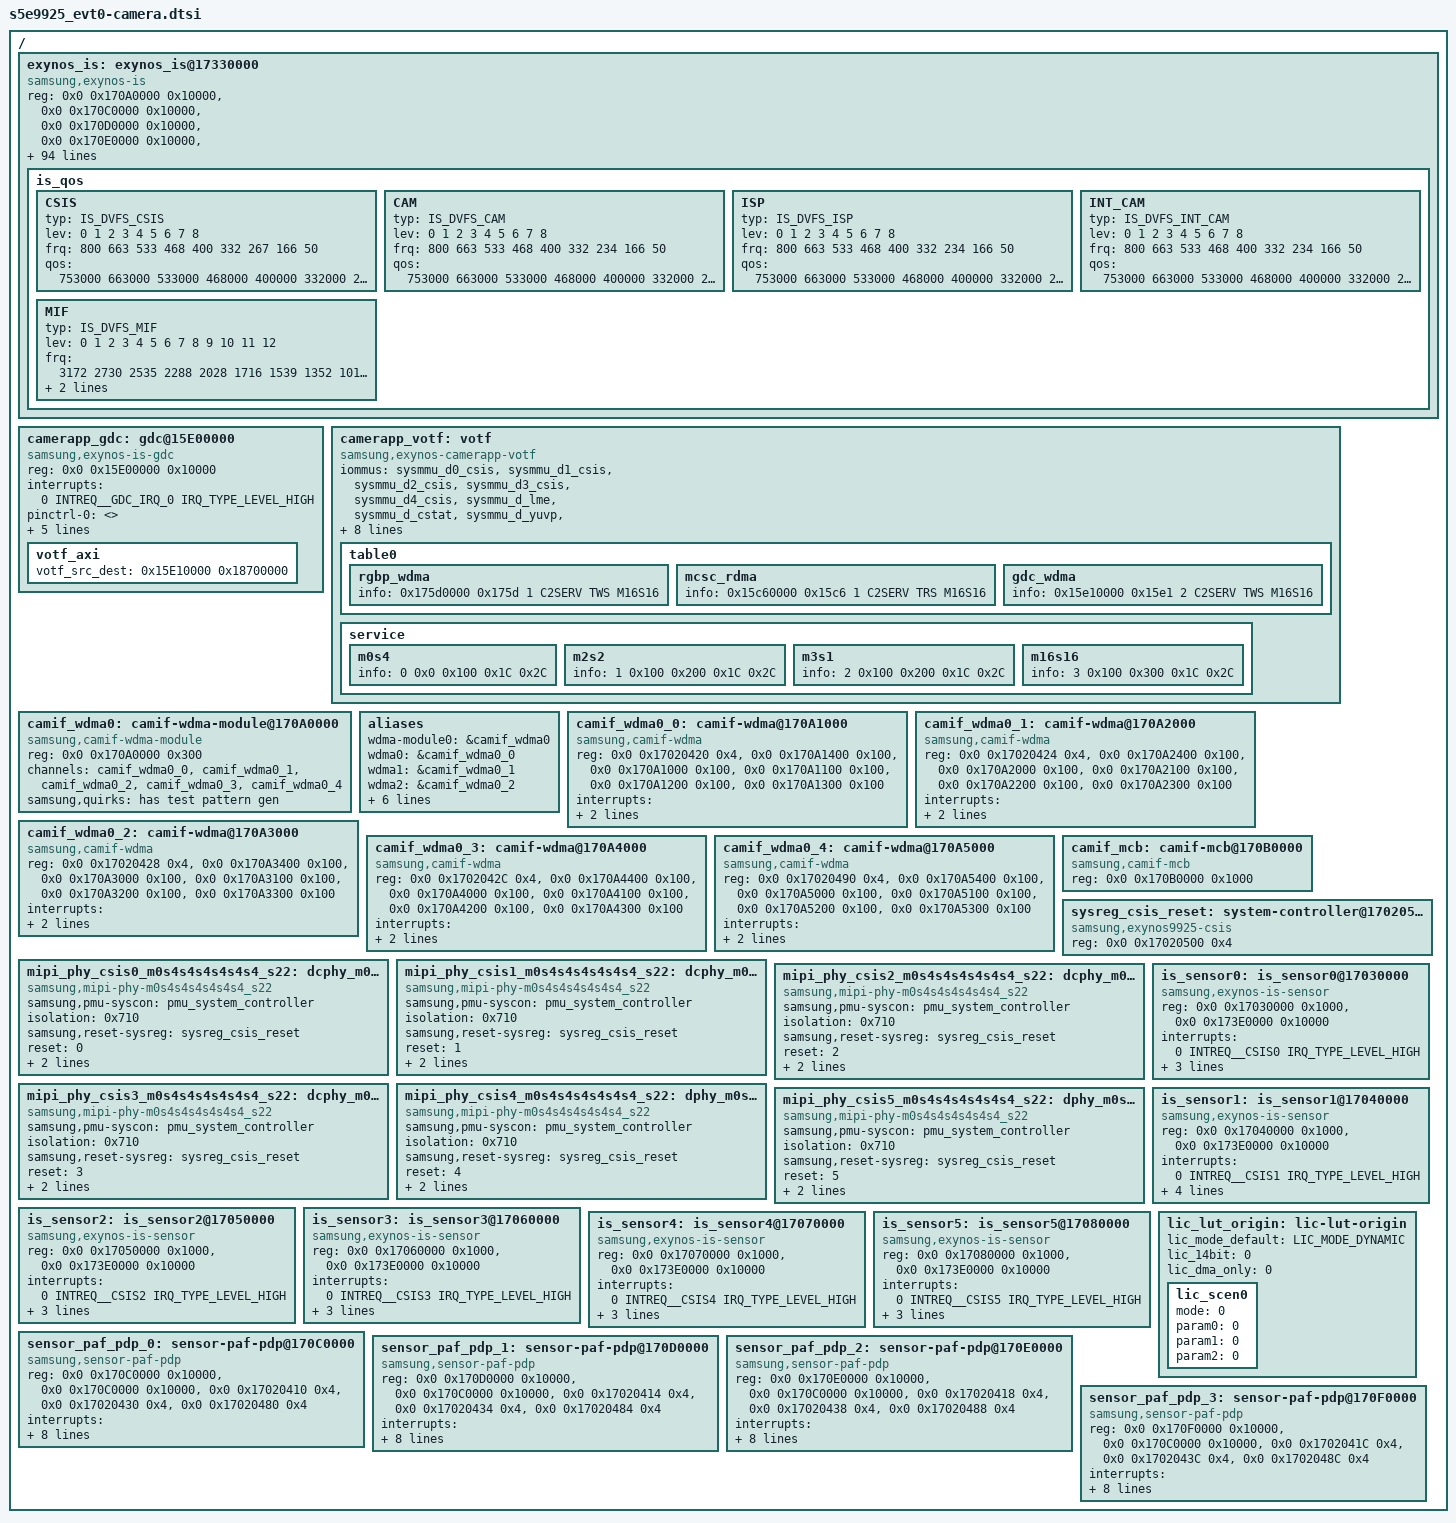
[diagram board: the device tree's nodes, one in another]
/*
 * SAMSUNG EXYNOS9925 SoC camera device tree source
 *
 * Copyright (c) 2020 Samsung Electronics Co., Ltd.
 *		http://www.samsung.com
 *
 * SAMSUNG EXYNOS9925 SoC camera device nodes are listed in this file.
 * EXYNOS9925 based board files can include this file and provide
 * values for board specfic bindings.
 *
 * This program is free software; you can redistribute it and/or modify
 * it under the terms of the GNU General Public License version 2 as
 * published by the Free Software Foundation.
 */

#include <dt-bindings/clock/s5e9925_evt0.h>
#include <dt-bindings/interrupt-controller/arm-gic.h>
#include <dt-bindings/interrupt-controller/s5e9925_evt0.h>
#include <dt-bindings/camera/exynos_is_dt.h>
#include <dt-bindings/camera/votf.h>
#include "s5e9925_evt0-pinctrl.dtsi"

/ {
	exynos_is: exynos_is@17330000 {
		compatible = "samsung,exynos-is";
		reg = <0x0 0x170A0000 0x10000>, /* CSIS_WDMA */
			<0x0 0x170C0000 0x10000>, /* PDP_CORE0 */
			<0x0 0x170D0000 0x10000>, /* PDP_CORE1 */
			<0x0 0x170E0000 0x10000>, /* PDP_CORE2 */
			<0x0 0x170F0000 0x10000>, /* PDP_CORE3 */
			<0x0 0x18440000 0x10000>, /* CSTAT0 */
			<0x0 0x18450000 0x10000>, /* CSTAT1 */
			<0x0 0x18460000 0x10000>, /* CSTAT2 */
			<0x0 0x18470000 0x10000>, /* CSTAT3 */
			<0x0 0x170A0000 0x10000>, /* ZSL/STRIP DMA  */
			<0x0 0x17730000 0x10000>, /* LME */
			<0x0 0x15F80000 0x10000>, /* BYRP */
			<0x0 0x175B0000 0x10000>, /* RGBP */
			<0x0 0x17430000 0x10000>, /* DRCP */
			<0x0 0x17B00000 0x10000>, /* MCFP */
			<0x0 0x18080000 0x10000>, /* YUVP */
			<0x0 0x15C40000 0x10000>; /* MCSC */
		interrupts = <0 INTREQ__CSTAT_CH0_0 IRQ_TYPE_LEVEL_HIGH>, /*CSTAT0_0 */
			<0 INTREQ__CSTAT_CH0_1 IRQ_TYPE_LEVEL_HIGH>,      /* CSTAT0_1 */
			<0 INTREQ__CSTAT_CH1_0 IRQ_TYPE_LEVEL_HIGH>,      /* CSTAT1_0 */
			<0 INTREQ__CSTAT_CH1_1 IRQ_TYPE_LEVEL_HIGH>,      /* CSTAT1_1 */
			<0 INTREQ__CSTAT_CH2_0 IRQ_TYPE_LEVEL_HIGH>,      /* CSTAT2_0 */
			<0 INTREQ__CSTAT_CH2_1 IRQ_TYPE_LEVEL_HIGH>,      /* CSTAT2_1 */
			<0 INTREQ__CSTAT_CH3_0 IRQ_TYPE_LEVEL_HIGH>,      /* CSTAT3_0 */
			<0 INTREQ__CSTAT_CH3_1 IRQ_TYPE_LEVEL_HIGH>,      /* CSTAT3_1 */
			<0 INTREQ__LME_O_INT0 IRQ_TYPE_LEVEL_HIGH>,       /* LME_0 */
			<0 INTREQ__BYRP_0 IRQ_TYPE_LEVEL_HIGH>,           /* BYRP_0 */
			<0 INTREQ__BYRP_1 IRQ_TYPE_LEVEL_HIGH>,           /* BYRP_1 */
			<0 INTREQ__RGBP_0 IRQ_TYPE_LEVEL_HIGH>,           /* RGBP_0 */
			<0 INTREQ__RGBP_1 IRQ_TYPE_LEVEL_HIGH>,           /* RGBP_1 */
			<0 INTREQ__MCFP_0 IRQ_TYPE_LEVEL_HIGH>,           /* MCFP_0 */
			<0 INTREQ__MCFP_1 IRQ_TYPE_LEVEL_HIGH>,           /* MCFP_1 */
			<0 INTREQ__YUVP_0 IRQ_TYPE_LEVEL_HIGH>,           /* YUVP_0 */
			<0 INTREQ__YUVP_1 IRQ_TYPE_LEVEL_HIGH>,           /* YUVP_1 */
			<0 INTREQ__DRCP_0 IRQ_TYPE_LEVEL_HIGH>,           /* DRCP_0 */
			<0 INTREQ__DRCP_1 IRQ_TYPE_LEVEL_HIGH>,           /* DRCP_1 */
			<0 INTREQ__MCSC_INTREQ_0 IRQ_TYPE_LEVEL_HIGH>,    /* MCSC_0 */
			<0 INTREQ__MCSC_INTREQ_1 IRQ_TYPE_LEVEL_HIGH>;    /* MCSC_1 */
		pinctrl-names = "default","release";
		pinctrl-0 = <>;
		pinctrl-1 = <>;
		clocks = <&clock GATE_DFTMUX_CMU_QCH_CIS_CLK0>,
		      <&clock GATE_DFTMUX_CMU_QCH_CIS_CLK1>,
		      <&clock GATE_DFTMUX_CMU_QCH_CIS_CLK2>,
		      <&clock GATE_DFTMUX_CMU_QCH_CIS_CLK3>,
		      <&clock GATE_DFTMUX_CMU_QCH_CIS_CLK4>,
		      <&clock GATE_DFTMUX_CMU_QCH_CIS_CLK5>,
		      <&clock GATE_DFTMUX_CMU_QCH_CIS_CLK6>,
		      <&clock GATE_DFTMUX_CMU_QCH_CIS_CLK7>,

		      <&clock DOUT_DIV_CLKCMU_CIS_CLK0>,
		      <&clock DOUT_DIV_CLKCMU_CIS_CLK1>,
		      <&clock DOUT_DIV_CLKCMU_CIS_CLK2>,
		      <&clock DOUT_DIV_CLKCMU_CIS_CLK3>,
		      <&clock DOUT_DIV_CLKCMU_CIS_CLK4>,
		      <&clock DOUT_DIV_CLKCMU_CIS_CLK5>,
		      <&clock DOUT_DIV_CLKCMU_CIS_CLK6>,
		      <&clock DOUT_DIV_CLKCMU_CIS_CLK7>,

		      <&clock GATE_CSIS_PDP_QCH_DMA>,

		      <&clock GATE_MIPI_PHY_LINK_WRAP_QCH_CSIS0>,
		      <&clock GATE_MIPI_PHY_LINK_WRAP_QCH_CSIS1>,
		      <&clock GATE_MIPI_PHY_LINK_WRAP_QCH_CSIS2>,
		      <&clock GATE_MIPI_PHY_LINK_WRAP_QCH_CSIS3>,
		      <&clock GATE_MIPI_PHY_LINK_WRAP_QCH_CSIS4>,
		      <&clock GATE_MIPI_PHY_LINK_WRAP_QCH_CSIS5>,
		      <&clock GATE_MIPI_PHY_LINK_WRAP_QCH_CSIS6>,

		      <&clock GATE_CSIS_PDP_QCH_PDP>,
		      <&clock GATE_LH_AST_SI_OTF0_CSISCSTAT_QCH>,
		      <&clock GATE_LH_AST_SI_OTF1_CSISCSTAT_QCH>,
		      <&clock GATE_LH_AST_SI_OTF2_CSISCSTAT_QCH>,
		      <&clock GATE_LH_AST_SI_OTF3_CSISCSTAT_QCH>,
		      <&clock GATE_LME_QCH_0>,
		      <&clock GATE_LME_QCH_1>,
		      <&clock GATE_MCFP_QCH>,
		      <&clock GATE_YUVP_QCH>,
		      <&clock GATE_MCSC_QCH>;
		      /* <&clock GATE_GDC_QCH>; */
		clock-names = "GATE_DFTMUX_CMU_QCH_CIS_CLK0",
			"GATE_DFTMUX_CMU_QCH_CIS_CLK1",
			"GATE_DFTMUX_CMU_QCH_CIS_CLK2",
			"GATE_DFTMUX_CMU_QCH_CIS_CLK3",
			"GATE_DFTMUX_CMU_QCH_CIS_CLK4",
			"GATE_DFTMUX_CMU_QCH_CIS_CLK5",
			"GATE_DFTMUX_CMU_QCH_CIS_CLK6",
			"GATE_DFTMUX_CMU_QCH_CIS_CLK7",

			"DOUT_DIV_CLKCMU_CIS_CLK0",
			"DOUT_DIV_CLKCMU_CIS_CLK1",
			"DOUT_DIV_CLKCMU_CIS_CLK2",
			"DOUT_DIV_CLKCMU_CIS_CLK3",
			"DOUT_DIV_CLKCMU_CIS_CLK4",
			"DOUT_DIV_CLKCMU_CIS_CLK5",
			"DOUT_DIV_CLKCMU_CIS_CLK6",
			"DOUT_DIV_CLKCMU_CIS_CLK7",

			"GATE_CSIS_PDP_QCH_DMA",

			"GATE_MIPI_PHY_LINK_WRAP_QCH_CSIS0",
			"GATE_MIPI_PHY_LINK_WRAP_QCH_CSIS1",
			"GATE_MIPI_PHY_LINK_WRAP_QCH_CSIS2",
			"GATE_MIPI_PHY_LINK_WRAP_QCH_CSIS3",
			"GATE_MIPI_PHY_LINK_WRAP_QCH_CSIS4",
			"GATE_MIPI_PHY_LINK_WRAP_QCH_CSIS5",
			"GATE_MIPI_PHY_LINK_WRAP_QCH_CSIS6",

			"GATE_CSIS_PDP_QCH_PDP",
			"GATE_LH_AST_SI_OTF0_CSISCSTAT_QCH",
			"GATE_LH_AST_SI_OTF1_CSISCSTAT_QCH",
			"GATE_LH_AST_SI_OTF2_CSISCSTAT_QCH",
			"GATE_LH_AST_SI_OTF3_CSISCSTAT_QCH",
			"GATE_LME_QCH_0",
			"GATE_LME_QCH_1",
			"GATE_MCFP_QCH",
			"GATE_YUVP_QCH",
			"GATE_MCSC_QCH";
			/* "GATE_GDC_QCH"; */
		status = "ok";
		iommus = <&sysmmu_d0_csis>,
			<&sysmmu_d1_csis>,
			<&sysmmu_d2_csis>,
			<&sysmmu_d3_csis>,
			<&sysmmu_d4_csis>,
			<&sysmmu_d_lme>,
			<&sysmmu_d_cstat>,
			<&sysmmu_d_yuvp>,
			<&sysmmu_d1_mcsc>,
			<&sysmmu_d2_mcsc>,
			<&sysmmu_d0_mcfp>,
			<&sysmmu_d1_mcfp>,
			<&sysmmu_d2_mcfp>,
			<&sysmmu_d3_mcfp>,
			<&sysmmu_d4_mcfp>,
			<&sysmmu_d5_mcfp>,
			<&sysmmu_d0_rgbp>,
			<&sysmmu_d1_rgbp>,
			<&sysmmu_d_drcp>,
			<&sysmmu_d_byrp>;
		samsung,iommu-group = <&iommu_group_is>;
		#cooling-cells = <2>; /* min followed by max */
		ewf-index = <EWF_GRP_CAM>;
		list-scen-bts = "camera_default", "camera_heavy";
		num_of_3aa = <4>;
		num_of_lme = <1>;
		num_of_isp = <0>;
		num_of_byrp = <1>;
		num_of_rgbp = <1>;
		num_of_mcsc = <1>;
		num_of_vra = <0>;
		num_of_clh = <0>;
		num_of_ypp = <1>;
		num_of_mcfp = <1>;

		memory-region = <&camera_bin>;
		samsung,tzmp;

		is_qos {
			CSIS { /* CSIS, CSTAT */
				typ = <IS_DVFS_CSIS>;
				lev = <0      1      2      3      4      5      6      7      8>;
				frq = <800    663    533    468    400    332    267    166    50>;
				qos = <753000 663000 533000 468000 400000 332000 267000 166000 50000>;
			};

			CAM { /* BYRP, RGBP, MCSC, GDC */
				typ = <IS_DVFS_CAM>;
				lev = <0      1      2      3      4      5      6      7      8>;
				frq = <800    663    533    468    400    332    234    166    50>;
				qos = <753000 663000 533000 468000 400000 332000 234000 166000 50000>;
			};

			ISP { /* MCFP, YUVP */
				typ = <IS_DVFS_ISP>;
				lev = <0      1      2      3      4      5      6      7      8>;
				frq = <800    663    533    468    400    332    234    166    50>;
				qos = <753000 663000 533000 468000 400000 332000 234000 166000 50000>;
			};

			INT_CAM { /* LME */
				typ = <IS_DVFS_INT_CAM>;
				lev = <0      1      2      3      4      5      6      7      8>;
				frq = <800    663    533    468    400    332    234    166    50>;
				qos = <753000 663000 533000 468000 400000 332000 234000 166000 50000>;
			};

			MIF {
				typ = <IS_DVFS_MIF>;
				lev = <0       1       2       3       4       5       6       7       8       9      10     11     12>;
				frq = <3172    2730    2535    2288    2028    1716    1539    1352    1014    845    676    546    421>;
				qos = <3172000 2730000 2535000 2288000 2028000 1716000 1539000 1352000 1014000 845000 676000 546000 421000>;
			};
		};
	};

	camerapp_gdc: gdc@15E00000 {
		compatible = "samsung,exynos-is-gdc";
		reg = <0x0 0x15E00000 0x10000>; /* GDC */
		interrupts = <0 INTREQ__GDC_IRQ_0 IRQ_TYPE_LEVEL_HIGH>; /* GDC */
		pinctrl-names = "default","release";
		pinctrl-0 = <>;
		pinctrl-1 = <>;
		clocks = <&clock GATE_MCSC_QCH>;
		clock-names = "gate";
		status = "okay";
		iommus = <&sysmmu_d0_mcsc>;
		samsung,iommu-group = <&iommu_group_camerapp_gdc>;
		#cooling-cells = <2>; /* min followed by max */
		dma-coherent;

		votf_axi {
			votf_src_dest = <0x15E10000 0x18700000>;
		};
	};

	camerapp_votf: votf {
		compatible = "samsung,exynos-camerapp-votf";
		iommus = <&sysmmu_d0_csis>,
			<&sysmmu_d1_csis>,
			<&sysmmu_d2_csis>,
			<&sysmmu_d3_csis>,
			<&sysmmu_d4_csis>,
			<&sysmmu_d_lme>,
			<&sysmmu_d_cstat>,
			<&sysmmu_d_yuvp>,
			<&sysmmu_d1_mcsc>,
			<&sysmmu_d2_mcsc>,
			<&sysmmu_d0_mcfp>,
			<&sysmmu_d1_mcfp>,
			<&sysmmu_d2_mcfp>,
			<&sysmmu_d3_mcfp>,
			<&sysmmu_d4_mcfp>,
			<&sysmmu_d5_mcfp>,
			<&sysmmu_d0_rgbp>,
			<&sysmmu_d1_rgbp>,
			<&sysmmu_d_drcp>,
			<&sysmmu_d_byrp>;
		samsung,iommu-group = <&iommu_group_is>;
		status = "okay";
		use_axi;

		table0{
			/* base address, ip num, id cnt, C2SERV/C2AGENT, TWS/TRS, module type */
			/*
			csis_wdma0 { info = <0x17380000 0x1738 16 C2SERV TWS M16S16>; };
			csis_wdma1 { info = <0x17390000 0x1739 4 C2SERV TWS M16S16>; };
			pdp_rdma   { info = <0x173a0000 0x173a 4 C2SERV TRS M16S16>; };
			byrp_wdma  { info = <0x15fa0000 0x15fa 2 C2SERV TWS M16S16>; };
			byrp_rdma  { info = <0x15fc0000 0x15fc 1 C2SERV TRS M16S16>; };
			cstat_wdma0 { info = <0x18510000 0x1851 16 C2SERV TWS M16S16>; };
			cstat_wdma1 { info = <0x18520000 0x1852 16 C2SERV TWS M16S16>; };
			cstat_wdma2 { info = <0x18530000 0x1853 4 C2SERV TWS M16S16>; };
			cstat_rdma { info = <0x18500000 0x1850 4 C2SERV TRS M16S16>; };
			rgbp_rdma { info = <0x175c0000 0x175c 4 C2SERV TWS M16S16>; };
			*/
			rgbp_wdma { info = <0x175d0000 0x175d 1 C2SERV TWS M16S16>; };
			mcsc_rdma  { info = <0x15c60000 0x15c6 1 C2SERV TRS M16S16>; };
			gdc_wdma   { info = <0x15e10000 0x15e1 2 C2SERV TWS M16S16>; };
			/*
			mcsc_wdma  { info = <0x16c50000 0x15c5 16 C2SERV TWS M16S16>; };
			gdc_rdma   { info = <0x15e20000 0x15e2 2 C2SERV TRS M16S16>; };
			lme_rdma   { info = <0x17740000 0x1774 16 C2SERV TRS M16S16>; };
			*/
		};

		service {
			/* num, tws addr, trs addr, tws gap, trs gap */
			m0s4 { info = <0 0x0 0x100 0x1C 0x2C>; };
			m2s2 { info = <1 0x100 0x200 0x1C 0x2C>; };
			m3s1 { info = <2 0x100 0x200 0x1C 0x2C>; };
			m16s16 { info = <3 0x100 0x300 0x1C 0x2C>; };
		};
	};

	camif_wdma0: camif-wdma-module@170A0000 {
		compatible = "samsung,camif-wdma-module";
		reg = <0x0 0x170A0000 0x300>;
		reg-names = "ctl";
		channels = <&camif_wdma0_0>,
			<&camif_wdma0_1>,
			<&camif_wdma0_2>,
			<&camif_wdma0_3>,
			<&camif_wdma0_4>;
		samsung,quirks = "has test pattern gen";
	};

	aliases {
		wdma-module0 = &camif_wdma0;
	};

	camif_wdma0_0: camif-wdma@170A1000 {
		compatible = "samsung,camif-wdma";
		reg = <0x0 0x17020420 0x4>,	/* input MUX */
			<0x0 0x170A1400 0x100>,	/* CTL */
			<0x0 0x170A1000 0x100>,	/* VC0 */
			<0x0 0x170A1100 0x100>,	/* VC1 */
			<0x0 0x170A1200 0x100>,	/* VC2 */
			<0x0 0x170A1300 0x100>;	/* VC3 */
		reg-names = "mux", "ctl", "vc0", "vc1", "vc2", "vc3";
		interrupts = <GIC_SPI INTREQ__CSIS_DMA0 IRQ_TYPE_LEVEL_HIGH>;
		interrupt-names = "dma";
		module = <&camif_wdma0>;
	};

	camif_wdma0_1: camif-wdma@170A2000 {
		compatible = "samsung,camif-wdma";
		reg = <0x0 0x17020424 0x4>,	/* input MUX */
			<0x0 0x170A2400 0x100>,	/* CTL */
			<0x0 0x170A2000 0x100>,	/* VC0 */
			<0x0 0x170A2100 0x100>,	/* VC1 */
			<0x0 0x170A2200 0x100>,	/* VC2 */
			<0x0 0x170A2300 0x100>;	/* VC3 */
		reg-names = "mux", "ctl", "vc0", "vc1", "vc2", "vc3";
		interrupts = <GIC_SPI INTREQ__CSIS_DMA1 IRQ_TYPE_LEVEL_HIGH>;
		interrupt-names = "dma";
		module = <&camif_wdma0>;
	};

	camif_wdma0_2: camif-wdma@170A3000 {
		compatible = "samsung,camif-wdma";
		reg = <0x0 0x17020428 0x4>,	/* input MUX */
			<0x0 0x170A3400 0x100>,	/* CTL */
			<0x0 0x170A3000 0x100>,	/* VC0 */
			<0x0 0x170A3100 0x100>,	/* VC1 */
			<0x0 0x170A3200 0x100>,	/* VC2 */
			<0x0 0x170A3300 0x100>;	/* VC3 */
		reg-names = "mux", "ctl", "vc0", "vc1", "vc2", "vc3";
		interrupts = <GIC_SPI INTREQ__CSIS_DMA2 IRQ_TYPE_LEVEL_HIGH>;
		interrupt-names = "dma";
		module = <&camif_wdma0>;
	};

	camif_wdma0_3: camif-wdma@170A4000 {
		compatible = "samsung,camif-wdma";
		reg = <0x0 0x1702042C 0x4>,	/* input MUX */
			<0x0 0x170A4400 0x100>,	/* CTL */
			<0x0 0x170A4000 0x100>,	/* VC0 */
			<0x0 0x170A4100 0x100>,	/* VC1 */
			<0x0 0x170A4200 0x100>,	/* VC2 */
			<0x0 0x170A4300 0x100>;	/* VC3 */
		reg-names = "mux", "ctl", "vc0", "vc1", "vc2", "vc3";
		interrupts = <GIC_SPI INTREQ__CSIS_DMA3 IRQ_TYPE_LEVEL_HIGH>;
		interrupt-names = "dma";
		module = <&camif_wdma0>;
	};

	camif_wdma0_4: camif-wdma@170A5000 {
		compatible = "samsung,camif-wdma";
		reg = <0x0 0x17020490 0x4>,	/* input MUX */
			<0x0 0x170A5400 0x100>,	/* CTL */
			<0x0 0x170A5000 0x100>,	/* VC0 */
			<0x0 0x170A5100 0x100>,	/* VC1 */
			<0x0 0x170A5200 0x100>,	/* VC2 */
			<0x0 0x170A5300 0x100>;	/* VC3 */
		reg-names = "mux", "ctl", "vc0", "vc1", "vc2", "vc3";
		interrupts = <GIC_SPI INTREQ__CSIS_DMA4 IRQ_TYPE_LEVEL_HIGH>;
		interrupt-names = "dma";
		module = <&camif_wdma0>;
	};

	aliases {
		wdma0 = &camif_wdma0_0;
		wdma1 = &camif_wdma0_1;
		wdma2 = &camif_wdma0_2;
		wdma3 = &camif_wdma0_3;
		wdma4 = &camif_wdma0_4;
	};

	camif_mcb: camif-mcb@170B0000 {
		compatible = "samsung,camif-mcb";
		reg = <0x0 0x170B0000 0x1000>;
	};

	sysreg_csis_reset: system-controller@17020500 {
		compatible = "samsung,exynos9925-csis", "syscon";
		reg = <0x0 0x17020500 0x4>;
	};

	mipi_phy_csis0_m0s4s4s4s4s4s4_s22: dcphy_m0s4s4s4s4s4s4_s22_csi0@17020500 {
		/* DPHY 6.5 Gbps 4lane */
		/* CPHY 6.5 Gbps 3lane */
		compatible = "samsung,mipi-phy-m0s4s4s4s4s4s4_s22";
		samsung,pmu-syscon = <&pmu_system_controller>;
		isolation = <0x710>; /* PMU address offset */
		samsung,reset-sysreg = <&sysreg_csis_reset>;
		reset = <0>; /* reset bit */
		reg = <0x0 0x173E1300 0x500>;
		owner = <1>; /* 0: DSI,  1: CSI */
		#phy-cells = <1>;
	};

	mipi_phy_csis1_m0s4s4s4s4s4s4_s22: dcphy_m0s4s4s4s4s4s4_s22_csi1@17020500 {
		/* DPHY 6.5 Gbps 4lane */
		/* CPHY 6.5 Gbps 3lane */
		compatible = "samsung,mipi-phy-m0s4s4s4s4s4s4_s22";
		samsung,pmu-syscon = <&pmu_system_controller>;
		isolation = <0x710>; /* PMU address offset */
		samsung,reset-sysreg = <&sysreg_csis_reset>;
		reset = <1>; /* reset bit */
		reg = <0x0 0x173E1B00 0x500>;
		owner = <1>; /* 0: DSI,  1: CSI */
		#phy-cells = <1>;
	};

	mipi_phy_csis2_m0s4s4s4s4s4s4_s22: dcphy_m0s4s4s4s4s4s4_s22_csi2@17020500 {
		/* DPHY 6.5 Gbps 4lane */
		/* CPHY 6.5 Gbps 3lane */
		compatible = "samsung,mipi-phy-m0s4s4s4s4s4s4_s22";
		samsung,pmu-syscon = <&pmu_system_controller>;
		isolation = <0x710>; /* PMU address offset */
		samsung,reset-sysreg = <&sysreg_csis_reset>;
		reset = <2>; /* reset bit */
		reg = <0x0 0x173E2300 0x500>;
		owner = <1>; /* 0: DSI,  1: CSI */
		#phy-cells = <1>;
	};

	mipi_phy_csis3_m0s4s4s4s4s4s4_s22: dcphy_m0s4s4s4s4s4s4_s22_csi3@17020500 {
		/* DPHY 6.5 Gbps 4lane */
		/* CPHY 6.5 Gbps 3lane */
		compatible = "samsung,mipi-phy-m0s4s4s4s4s4s4_s22";
		samsung,pmu-syscon = <&pmu_system_controller>;
		isolation = <0x710>; /* PMU address offset */
		samsung,reset-sysreg = <&sysreg_csis_reset>;
		reset = <3>; /* reset bit */
		reg = <0x0 0x173E2B00 0x500>;
		owner = <1>; /* 0: DSI,  1: CSI */
		#phy-cells = <1>;
	};

	mipi_phy_csis4_m0s4s4s4s4s4s4_s22: dphy_m0s4s4s4s4s4s4_s22_csi4@17020500 {
		/* DPHY 6.5 Gbps 4lane */
		/* CPHY 6.5 Gbps 3lane */
		compatible = "samsung,mipi-phy-m0s4s4s4s4s4s4_s22";
		samsung,pmu-syscon = <&pmu_system_controller>;
		isolation = <0x710>; /* PMU address offset */
		samsung,reset-sysreg = <&sysreg_csis_reset>;
		reset = <4>; /* reset bit */
		reg = <0x0 0x173E3300 0x500>;
		owner = <1>; /* 0: DSI,  1: CSI */
		#phy-cells = <1>;
	};

	mipi_phy_csis5_m0s4s4s4s4s4s4_s22: dphy_m0s4s4s4s4s4s4_s22_csi5@17020500 {
		/* DPHY 6.5 Gbps 4lane */
		compatible = "samsung,mipi-phy-m0s4s4s4s4s4s4_s22";
		samsung,pmu-syscon = <&pmu_system_controller>;
		isolation = <0x710>; /* PMU address offset */
		samsung,reset-sysreg = <&sysreg_csis_reset>;
		reset = <5>; /* reset bit */
		reg = <0x0 0x173E3B00 0x500>;
		owner = <1>; /* 0: DSI,  1: CSI */
		#phy-cells = <1>;
	};

	is_sensor0: is_sensor0@17030000 {
		/* CSIS0 */
		compatible = "samsung,exynos-is-sensor";
		#address-cells = <1>;
		#size-cells = <1>;
		reg = <0x0 0x17030000 0x1000>, /* MIPI-CSI0 */
			<0x0 0x173E0000 0x10000>; /* PHY: M0S4S4S4S4S4S2 */
		reg-names = "csi", "phy";
		interrupts = <0 INTREQ__CSIS0 IRQ_TYPE_LEVEL_HIGH>; /*MIPI-CSI0 */
		interrupt-names = "csi";
		phys = <&mipi_phy_csis0_m0s4s4s4s4s4s4_s22 0>;
		phy-names = "csis_dphy";
		iommus = <&sysmmu_d0_csis>, <&sysmmu_d1_csis>;
		samsung,iommu-group = <&iommu_group_is>;
	};

	is_sensor1: is_sensor1@17040000 {
		/* CSIS1 */
		compatible = "samsung,exynos-is-sensor";
		#address-cells = <1>;
		#size-cells = <1>;
		reg = <0x0 0x17040000 0x1000>, /* MIPI-CSI1 */
			<0x0 0x173E0000 0x10000>; /* PHY: M0S4S4S4S4S4S2 */
		reg-names = "csi", "phy";
		interrupts = <0 INTREQ__CSIS1 IRQ_TYPE_LEVEL_HIGH>; /* MIPI-CSI1 */
		interrupt-names = "csi";
		phys = <&mipi_phy_csis1_m0s4s4s4s4s4s4_s22 0>;
		phy-names = "csis_dphy";
		iommus = <&sysmmu_d0_csis>, <&sysmmu_d1_csis>;
		samsung,iommu-group = <&iommu_group_is>;
		samsung,tzmp;
	};

	is_sensor2: is_sensor2@17050000 {
		/* CSIS2 */
		compatible = "samsung,exynos-is-sensor";
		#address-cells = <1>;
		#size-cells = <1>;
		reg = <0x0 0x17050000 0x1000>, /* MIPI-CSI2 */
			<0x0 0x173E0000 0x10000>; /* PHY: M0S4S4S4S4S4S2 */
		reg-names = "csi", "phy";
		interrupts = <0 INTREQ__CSIS2 IRQ_TYPE_LEVEL_HIGH>; /* MIPI-CSI2 */
		interrupt-names = "csi";
		phys = <&mipi_phy_csis2_m0s4s4s4s4s4s4_s22 0>;
		phy-names = "csis_dphy";
		iommus = <&sysmmu_d0_csis>, <&sysmmu_d1_csis>;
		samsung,iommu-group = <&iommu_group_is>;
	};

	is_sensor3: is_sensor3@17060000 {
		/* CSIS3 */
		compatible = "samsung,exynos-is-sensor";
		#address-cells = <1>;
		#size-cells = <1>;
		reg = <0x0 0x17060000 0x1000>, /* MIPI-CSI3 */
			<0x0 0x173E0000 0x10000>; /* PHY: M0S4S4S4S4S4S2 */
		reg-names = "csi", "phy";
		interrupts = <0 INTREQ__CSIS3 IRQ_TYPE_LEVEL_HIGH>; /* MIPI-CSI3 */
		interrupt-names = "csi";
		phys = <&mipi_phy_csis3_m0s4s4s4s4s4s4_s22 0>;
		phy-names = "csis_dphy";
		iommus = <&sysmmu_d0_csis>, <&sysmmu_d1_csis>;
		samsung,iommu-group = <&iommu_group_is>;
	};

	is_sensor4: is_sensor4@17070000 {
		/* CSIS4 */
		compatible = "samsung,exynos-is-sensor";
		#address-cells = <1>;
		#size-cells = <1>;
		reg = <0x0 0x17070000 0x1000>, /* MIPI-CSI4 */
			<0x0 0x173E0000 0x10000>; /* PHY: M0S4S4S4S4S4S2 */
		reg-names = "csi", "phy";
		interrupts = <0 INTREQ__CSIS4 IRQ_TYPE_LEVEL_HIGH>; /* MIPI-CSI4 */
		interrupt-names = "csi";
		phys = <&mipi_phy_csis4_m0s4s4s4s4s4s4_s22 0>;
		phy-names = "csis_dphy";
		iommus = <&sysmmu_d0_csis>, <&sysmmu_d1_csis>;
		samsung,iommu-group = <&iommu_group_is>;
	};

	is_sensor5: is_sensor5@17080000 {
		/* CSIS5 */
		compatible = "samsung,exynos-is-sensor";
		#address-cells = <1>;
		#size-cells = <1>;
		reg = <0x0 0x17080000 0x1000>, /* MIPI-CSI5 */
			<0x0 0x173E0000 0x10000>; /* PHY: M0S4S4S4S4S4S2 */
		reg-names = "csi", "phy";
		interrupts = <0 INTREQ__CSIS5 IRQ_TYPE_LEVEL_HIGH>; /* MIPI-CSI5 */
		interrupt-names = "csi";
		phys = <&mipi_phy_csis5_m0s4s4s4s4s4s4_s22 0>;
		phy-names = "csis_dphy";
		iommus = <&sysmmu_d0_csis>, <&sysmmu_d1_csis>;
		samsung,iommu-group = <&iommu_group_is>;
	};

	lic_lut_origin: lic-lut-origin {
		#define LIC_MODE_DYNAMIC	(0)
		#define LIC_MODE_STATIC		(1)
		#define LIC_PATH_OTF		(0)
		#define LIC_PATH_DMA		(1)

		lic_mode_default = <LIC_MODE_DYNAMIC>;
		lic_14bit = <0>;
		lic_dma_only = <0>; /* Use this when NOT using OTF input at all. */

		/*
		 * When DYNAMIC mode is selected, param means enable limitation for DMA path.
		 * Example:
		 * @ mode = <LIC_MODE_DYNAMIC>;
		 * @ param0 = <LIC_PATH_OTF>;
		 * @ param1 = <LIC_PATH_DMA>;
		 * @ param2 = <LIC_PATH_OTF>;
		 *
		 * When STATIC mode is selected, param means buffer size for each context.
		 * Example:
		 * @ mode = <LIC_MODE_STAIC>;
		 * @ param0 = <3584>;
		 * @ param1 = <3583>;
		 * @ param2 = <1>;
		 *
		 * The lic_scen0 is not abailable. If the index of LUT is "0", the selection is skipped.
		 */
		lic_scen0 { /* Reserved */
			mode = <0>;
			param0 = <0>;
			param1 = <0>;
			param2 = <0>;
		};
	};

	sensor_paf_pdp_0: sensor-paf-pdp@170C0000 {
		/* PDP CORE0 */
		compatible = "samsung,sensor-paf-pdp";
		reg = <0x0 0x170C0000 0x10000>, /* PDP CORE0 */
			<0x0 0x170C0000 0x10000>, /* PDP CORE0: For common regiser */
			<0x0 0x17020410 0x4>, /* PDP input mux(CSIS_PDP_SC_CON0) in SYSREG */
			<0x0 0x17020430 0x4>, /* PDP input vc mux(CSIS_PDP_VC_CON0) in SYSREG */
			<0x0 0x17020480 0x4>; /* CSIS_PDP_SC_PDP_IN_EN in SYSREG */
		reg-names = "core", "common", "mux", "vc_mux", "en";
		interrupts = <0 INTREQ__PDP0 IRQ_TYPE_LEVEL_HIGH>,
			<0 INTREQ__PDP1 IRQ_TYPE_LEVEL_HIGH>;

		/*
		 * Select input CSIS link & VC
		 * <csi0 csi1 csi2 csi3 csi4 csi5 csi6>
		 */
		mux =  <0 1 2 3 4 5 6>;
		vc_mux = <0x2 0x2 0x2 0x2 0x2 0x2 0x2>, /* IMG: VC0, H_AF: VC2 */
		       <0x10003 0x10003 0x10003 0x10003 0x10003 0x10003 0x10003>; /* IMG: VC1, H_AF: VC3 */

		en =  <0 1 2 3 4 5>; /* bit postion: <csi0 csi1 csi2 csi3 csi4 csi5> */
		leader; /* have RDMA & create video node */
		lic_lut = <&lic_lut_origin>;
	};

	sensor_paf_pdp_1: sensor-paf-pdp@170D0000 {
		/* PDP CORE0 */
		compatible = "samsung,sensor-paf-pdp";
		reg = <0x0 0x170D0000 0x10000>, /* PDP CORE0 */
			<0x0 0x170C0000 0x10000>, /* PDP CORE0: For common regiser */
			<0x0 0x17020414 0x4>, /* PDP input mux(CSIS_PDP_SC_CON0) in SYSREG */
			<0x0 0x17020434 0x4>, /* PDP input vc mux(CSIS_PDP_VC_CON0) in SYSREG */
			<0x0 0x17020484 0x4>; /* CSIS_PDP_SC_PDP_IN_EN in SYSREG */
		reg-names = "core", "common", "mux", "vc_mux", "en";
		interrupts = <0 INTREQ__PDP2 IRQ_TYPE_LEVEL_HIGH>,
			<0 INTREQ__PDP3 IRQ_TYPE_LEVEL_HIGH>;

		/*
		 * Select input CSIS link & VC
		 * <csi0 csi1 csi2 csi3 csi4 csi5 csi6>
		 */
		mux =  <0 1 2 3 4 5 6>;
		vc_mux = <0x2 0x2 0x2 0x2 0x2 0x2 0x2>, /* IMG: VC0, H_AF: VC2 */
		       <0x10003 0x10003 0x10003 0x10003 0x10003 0x10003 0x10003>; /* IMG: VC1, H_AF: VC3 */

		en =  <0 1 2 3 4 5>; /* bit postion: <csi0 csi1 csi2 csi3 csi4 csi5> */
		leader; /* have RDMA & create video node */
		lic_lut = <&lic_lut_origin>;
	};

	sensor_paf_pdp_2: sensor-paf-pdp@170E0000 {
		/* PDP CORE0 */
		compatible = "samsung,sensor-paf-pdp";
		reg = <0x0 0x170E0000 0x10000>, /* PDP CORE0 */
			<0x0 0x170C0000 0x10000>, /* PDP CORE0: For common regiser */
			<0x0 0x17020418 0x4>, /* PDP input mux(CSIS_PDP_SC_CON0) in SYSREG */
			<0x0 0x17020438 0x4>, /* PDP input vc mux(CSIS_PDP_VC_CON0) in SYSREG */
			<0x0 0x17020488 0x4>; /* CSIS_PDP_SC_PDP_IN_EN in SYSREG */
		reg-names = "core", "common", "mux", "vc_mux", "en";
		interrupts = <0 INTREQ__PDP4 IRQ_TYPE_LEVEL_HIGH>,
			<0 INTREQ__PDP5 IRQ_TYPE_LEVEL_HIGH>;

		/*
		 * Select input CSIS link & VC
		 * <csi0 csi1 csi2 csi3 csi4 csi5 csi6>
		 */
		mux =  <0 1 2 3 4 5 6>;
		vc_mux = <0x2 0x2 0x2 0x2 0x2 0x2 0x2>, /* IMG: VC0, H_AF: VC2 */
		       <0x10003 0x10003 0x10003 0x10003 0x10003 0x10003 0x10003>; /* IMG: VC1, H_AF: VC3 */

		en =  <0 1 2 3 4 5>; /* bit postion: <csi0 csi1 csi2 csi3 csi4 csi5> */
		leader; /* have RDMA & create video node */
		lic_lut = <&lic_lut_origin>;
	};

	sensor_paf_pdp_3: sensor-paf-pdp@170F0000 {
		/* PDP CORE0 */
		compatible = "samsung,sensor-paf-pdp";
		reg = <0x0 0x170F0000 0x10000>, /* PDP CORE0 */
			<0x0 0x170C0000 0x10000>, /* PDP CORE0: For common regiser */
			<0x0 0x1702041C 0x4>, /* PDP input mux(CSIS_PDP_SC_CON0) in SYSREG */
			<0x0 0x1702043C 0x4>, /* PDP input vc mux(CSIS_PDP_VC_CON0) in SYSREG */
			<0x0 0x1702048C 0x4>; /* CSIS_PDP_SC_PDP_IN_EN in SYSREG */
		reg-names = "core", "common", "mux", "vc_mux", "en";
		interrupts = <0 INTREQ__PDP6 IRQ_TYPE_LEVEL_HIGH>,
			<0 INTREQ__PDP7 IRQ_TYPE_LEVEL_HIGH>;

		/*
		 * Select input CSIS link & VC
		 * <csi0 csi1 csi2 csi3 csi4 csi5 csi6>
		 */
		mux =  <0 1 2 3 4 5 6>;
		vc_mux = <0x2 0x2 0x2 0x2 0x2 0x2 0x2>, /* IMG: VC0, H_AF: VC2 */
		       <0x10003 0x10003 0x10003 0x10003 0x10003 0x10003 0x10003>; /* IMG: VC1, H_AF: VC3 */

		en =  <0 1 2 3 4 5>; /* bit postion: <csi0 csi1 csi2 csi3 csi4 csi5> */
		leader; /* have RDMA & create video node */
		lic_lut = <&lic_lut_origin>;
	};

	aliases {
		pdp0 = &sensor_paf_pdp_0;
		pdp1 = &sensor_paf_pdp_1;
		pdp2 = &sensor_paf_pdp_2;
		pdp3 = &sensor_paf_pdp_3;
	};
};
